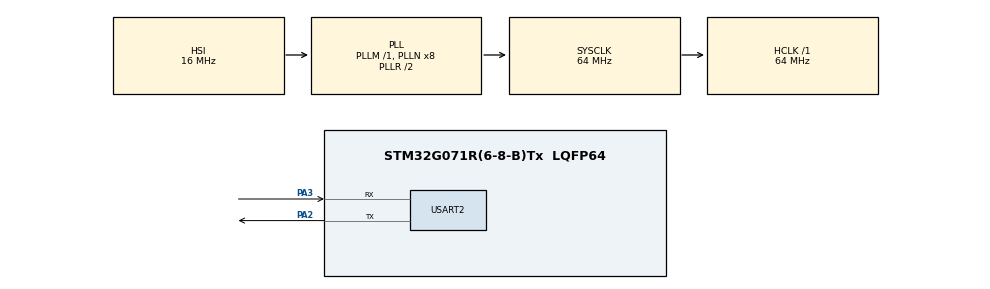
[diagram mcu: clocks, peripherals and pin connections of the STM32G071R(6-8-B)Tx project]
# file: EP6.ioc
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Dma.Request0=USART2_RX
Dma.Request1=USART2_TX
Dma.USART2_RX.0.Direction=DMA_PERIPH_TO_MEMORY
Dma.USART2_RX.0.EventEnable=DISABLE
Dma.USART2_RX.0.Instance=DMA1_Channel1
Dma.USART2_RX.0.MemDataAlignment=DMA_MDATAALIGN_BYTE
Dma.USART2_RX.0.MemInc=DMA_MINC_ENABLE
Dma.USART2_RX.0.Mode=DMA_NORMAL
Dma.USART2_RX.0.PeriphDataAlignment=DMA_PDATAALIGN_BYTE
Dma.USART2_RX.0.PeriphInc=DMA_PINC_DISABLE
Dma.USART2_RX.0.Polarity=HAL_DMAMUX_REQ_GEN_RISING
Dma.USART2_RX.0.Priority=DMA_PRIORITY_LOW
Dma.USART2_RX.0.RequestNumber=1
Dma.USART2_RX.0.SignalID=NONE
Dma.USART2_RX.0.SyncEnable=DISABLE
Dma.USART2_RX.0.SyncPolarity=HAL_DMAMUX_SYNC_NO_EVENT
Dma.USART2_RX.0.SyncRequestNumber=1
Dma.USART2_RX.0.SyncSignalID=NONE
Dma.USART2_TX.1.Direction=DMA_MEMORY_TO_PERIPH
Dma.USART2_TX.1.EventEnable=DISABLE
Dma.USART2_TX.1.Instance=DMA1_Channel2
Dma.USART2_TX.1.MemDataAlignment=DMA_MDATAALIGN_BYTE
Dma.USART2_TX.1.MemInc=DMA_MINC_ENABLE
Dma.USART2_TX.1.Mode=DMA_NORMAL
Dma.USART2_TX.1.PeriphDataAlignment=DMA_PDATAALIGN_BYTE
Dma.USART2_TX.1.PeriphInc=DMA_PINC_DISABLE
Dma.USART2_TX.1.Polarity=HAL_DMAMUX_REQ_GEN_RISING
Dma.USART2_TX.1.Priority=DMA_PRIORITY_LOW
Dma.USART2_TX.1.RequestNumber=1
Dma.USART2_TX.1.SignalID=NONE
Dma.USART2_TX.1.SyncEnable=DISABLE
Dma.USART2_TX.1.SyncPolarity=HAL_DMAMUX_SYNC_NO_EVENT
Dma.USART2_TX.1.SyncRequestNumber=1
Dma.USART2_TX.1.SyncSignalID=NONE
Mcu.Family=STM32G0
Mcu.Name=STM32G071R(6-8-B)Tx
Mcu.Package=LQFP64
NVIC.DMA1_Channel1_IRQn=true\:0\:0\:false\:false\:true\:false\:true\:true
NVIC.DMA1_Channel2_3_IRQn=true\:0\:0\:false\:false\:true\:false\:true\:true
NVIC.USART2_IRQn=true\:0\:0\:false\:false\:true\:true\:true\:true
PA2.Mode=Asynchronous
PA2.Signal=USART2_TX
PA3.Mode=Asynchronous
PA3.Signal=USART2_RX
ProjectManager.HeapSize=0x200
ProjectManager.StackSize=0x400
ProjectManager.TargetToolchain=STM32CubeIDE
RCC.ADCFreq_Value=64000000
RCC.AHBFreq_Value=64000000
RCC.CortexFreq_Value=64000000
RCC.EXTERNAL_CLOCK_VALUE=48000
RCC.HCLKFreq_Value=64000000
RCC.HSE_VALUE=8000000
RCC.HSI_VALUE=16000000
RCC.LSE_VALUE=32768
RCC.SYSCLKFreq_VALUE=64000000
RCC.SYSCLKSource=RCC_SYSCLKSOURCE_PLLCLK
RCC.VCOOutputFreq_Value=128000000
USART2.VirtualMode-Asynchronous=VM_ASYNC
board=custom

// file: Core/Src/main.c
/* USER CODE BEGIN Header */
/**
  ******************************************************************************
  * @file           : main.c
  * @brief          : Main program body
  ******************************************************************************
  * @attention
  *
  * Copyright (c) 2025 STMicroelectronics.
  * All rights reserved.
  *
  * This software is licensed under terms that can be found in the LICENSE file
  * in the root directory of this software component.
  * If no LICENSE file comes with this software, it is provided AS-IS.
  *
  ******************************************************************************
  */
/* USER CODE END Header */
#include "main.h"
#include "dma.h"
#include "usart.h"
#include "gpio.h"

/* USER CODE BEGIN PV */
uint8_t u8RxBuffer[10];
uint8_t u8TxBuffer[10] = {0x31,0x32,0x33,0x34,0x35,0x36,0x37,0x38,0x39,0x30};
/* USER CODE END PV */

void SystemClock_Config(void);
/* USER CODE BEGIN PFP */
void UartCallback(UART_HandleTypeDef *huart);
/* USER CODE END PFP */

int main(void)
{

  /* MCU Configuration--------------------------------------------------------*/

  /* Reset of all peripherals, Initializes the Flash interface and the Systick. */
  HAL_Init();

  /* Configure the system clock */
  SystemClock_Config();

  /* Initialize all configured peripherals */
  MX_GPIO_Init();
  MX_DMA_Init();
  MX_USART2_UART_Init();
  /* USER CODE BEGIN 2 */
  HAL_UART_Transmit(&huart2,u8TxBuffer, 10, 100);
  HAL_UART_RegisterCallback(&huart2, HAL_UART_RX_COMPLETE_CB_ID, UartCallback);
  HAL_UART_Receive_IT(&huart2, u8RxBuffer, 1);
  /* USER CODE END 2 */

  /* Infinite loop */
  while (1)
  {

    /* USER CODE BEGIN 3 */
	  HAL_UART_Transmit_DMA(&huart2, (uint8_t *) "Hacker Transmit\r\n", sizeof("Hacker Transmit\r\n"));
	  HAL_Delay(500);
  }
  /* USER CODE END 3 */
}

void SystemClock_Config(void)
{
  RCC_OscInitTypeDef RCC_OscInitStruct = {0};
  RCC_ClkInitTypeDef RCC_ClkInitStruct = {0};

  /** Configure the main internal regulator output voltage
  */
  HAL_PWREx_ControlVoltageScaling(PWR_REGULATOR_VOLTAGE_SCALE1);

  /** Initializes the RCC Oscillators according to the specified parameters
  * in the RCC_OscInitTypeDef structure.
  */
  RCC_OscInitStruct.OscillatorType = RCC_OSCILLATORTYPE_HSI;
  RCC_OscInitStruct.HSIState = RCC_HSI_ON;
  RCC_OscInitStruct.HSIDiv = RCC_HSI_DIV1;
  RCC_OscInitStruct.HSICalibrationValue = RCC_HSICALIBRATION_DEFAULT;
  RCC_OscInitStruct.PLL.PLLState = RCC_PLL_ON;
  RCC_OscInitStruct.PLL.PLLSource = RCC_PLLSOURCE_HSI;
  RCC_OscInitStruct.PLL.PLLM = RCC_PLLM_DIV1;
  RCC_OscInitStruct.PLL.PLLN = 8;
  RCC_OscInitStruct.PLL.PLLP = RCC_PLLP_DIV2;
  RCC_OscInitStruct.PLL.PLLQ = RCC_PLLQ_DIV2;
  RCC_OscInitStruct.PLL.PLLR = RCC_PLLR_DIV2;
  if (HAL_RCC_OscConfig(&RCC_OscInitStruct) != HAL_OK)
  {
    Error_Handler();
  }

  /** Initializes the CPU, AHB and APB buses clocks
  */
  RCC_ClkInitStruct.ClockType = RCC_CLOCKTYPE_HCLK|RCC_CLOCKTYPE_SYSCLK
                              |RCC_CLOCKTYPE_PCLK1;
  RCC_ClkInitStruct.SYSCLKSource = RCC_SYSCLKSOURCE_PLLCLK;
  RCC_ClkInitStruct.AHBCLKDivider = RCC_SYSCLK_DIV1;
  RCC_ClkInitStruct.APB1CLKDivider = RCC_HCLK_DIV1;

  if (HAL_RCC_ClockConfig(&RCC_ClkInitStruct, FLASH_LATENCY_2) != HAL_OK)
  {
    Error_Handler();
  }
}

/* USER CODE BEGIN 4 */
void HAL_UART_RxCpltCallback(UART_HandleTypeDef *huart)
{
	HAL_UART_Receive_IT(huart, u8RxBuffer, 10);
}

void UartCallback(UART_HandleTypeDef *huart)
{
	HAL_UART_Receive_IT(&huart2, u8RxBuffer, 10);
}
/* USER CODE END 4 */

void Error_Handler(void)
{
  __disable_irq();
  while (1)
  {
  }
}
